# PIC32MX154F128D register map
Vendor: Microchip
Registers are 32-bit, read-write, reset 0x0 unless marked. A register's access mark holds for its fields unless they carry their own. Addresses are absolute, and some are shared; only a register's first bit layout is shown; [hi:lo] are bit positions; 'fields as' and 'values as' point back to an identical list.

## RTCC
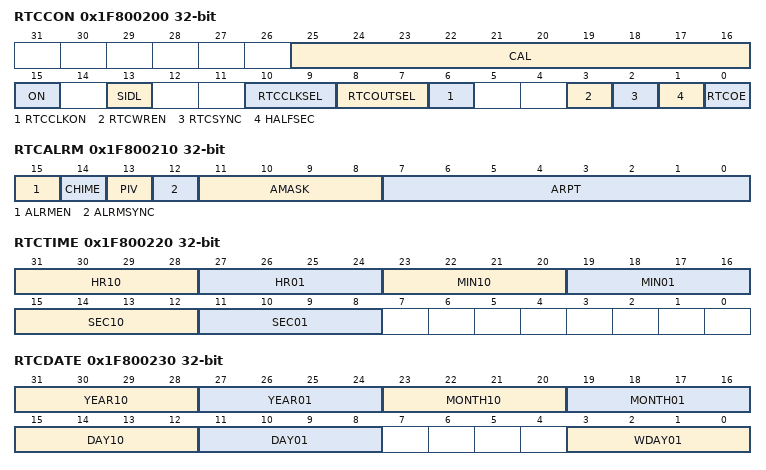
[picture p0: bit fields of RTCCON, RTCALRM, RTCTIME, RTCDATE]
0x1F800200 RTCCON
  [25:16] CAL, [15] ON, [13] SIDL, [10:9] RTCCLKSEL, [8:7] RTCOUTSEL, [6] RTCCLKON, [3] RTCWREN, [2] RTCSYNC ro, [1] HALFSEC ro, [0] RTCOE
0x1F800210 RTCALRM
  [15] ALRMEN, [14] CHIME, [13] PIV, [12] ALRMSYNC, [11:8] AMASK, [7:0] ARPT
0x1F800220 RTCTIME reset not defined — (power-on value 000xxxxxxxxxxxxx0xxxxxxx--------)
  [31:28] HR10, [27:24] HR01, [23:20] MIN10, [19:16] MIN01, [15:12] SEC10, [11:8] SEC01
0x1F800230 RTCDATE reset not defined — (power-on value xxxxxxxx000xxxxx00xxxxxx----0xxx)
  [31:28] YEAR10, [27:24] YEAR01, [23:20] MONTH10, [19:16] MONTH01, [15:12] DAY10, [11:8] DAY01, [3:0] WDAY01
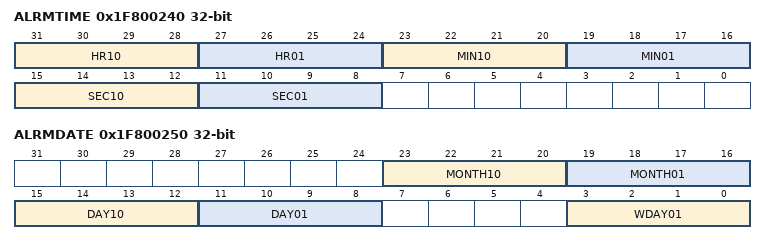
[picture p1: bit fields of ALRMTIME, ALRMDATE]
0x1F800240 ALRMTIME reset not defined — (power-on value 000xxxxx0xxxxxxx0xxxxxxx--------)
  fields as RTCTIME
0x1F800250 ALRMDATE reset not defined — (power-on value --------000xxxxx00xxxxxx----0xxx)
  [23:20] MONTH10, [19:16] MONTH01, [15:12] DAY10, [11:8] DAY01, [3:0] WDAY01

## TMR1
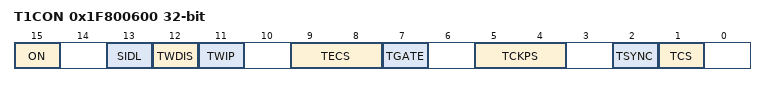
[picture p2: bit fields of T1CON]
0x1F800600 T1CON
  [15] ON, [13] SIDL, [12] TWDIS, [11] TWIP, [9:8] TECS, [7] TGATE, [5:4] TCKPS, [2] TSYNC, [1] TCS
0x1F800610 TMR1
0x1F800620 PR1 reset 0xFFFF

## TMR2
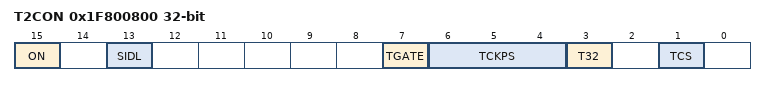
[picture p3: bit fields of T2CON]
0x1F800800 T2CON
  [15] ON, [13] SIDL, [7] TGATE, [6:4] TCKPS, [3] T32, [1] TCS
0x1F800810 TMR2
0x1F800820 PR2 reset 0xFFFF

## TMR3
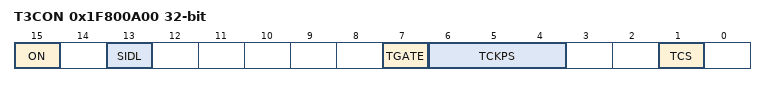
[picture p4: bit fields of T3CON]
0x1F800A00 T3CON
  [15] ON, [13] SIDL, [7] TGATE, [6:4] TCKPS, [1] TCS
0x1F800A10 TMR3
0x1F800A20 PR3 reset 0xFFFF

## TMR4
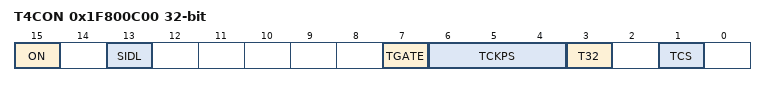
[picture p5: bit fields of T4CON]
0x1F800C00 T4CON
  [15] ON, [13] SIDL, [7] TGATE, [6:4] TCKPS, [3] T32, [1] TCS
0x1F800C10 TMR4
0x1F800C20 PR4 reset 0xFFFF

## TMR5
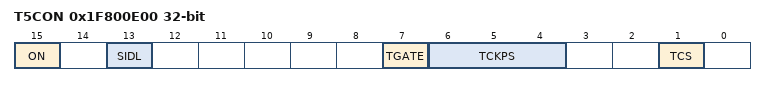
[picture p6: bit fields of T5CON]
0x1F800E00 T5CON
  [15] ON, [13] SIDL, [7] TGATE, [6:4] TCKPS, [1] TCS
0x1F800E10 TMR5
0x1F800E20 PR5 reset 0xFFFF

## ICAP1
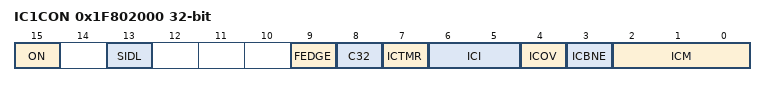
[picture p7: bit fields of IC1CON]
0x1F802000 IC1CON
  [15] ON, [13] SIDL, [9] FEDGE, [8] C32, [7] ICTMR, [6:5] ICI, [4] ICOV ro, [3] ICBNE ro, [2:0] ICM
0x1F802010 IC1BUF ro reset not defined — (power-on value xxxxxxxxxxxxxxxxxxxxxxxxxxxxxxxx)

## ICAP2
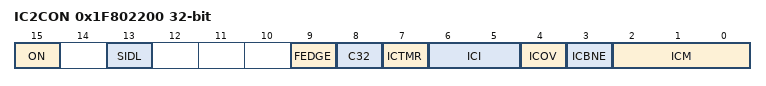
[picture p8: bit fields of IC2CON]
0x1F802200 IC2CON
  [15] ON, [13] SIDL, [9] FEDGE, [8] C32, [7] ICTMR, [6:5] ICI, [4] ICOV ro, [3] ICBNE ro, [2:0] ICM
0x1F802210 IC2BUF ro reset not defined — (power-on value xxxxxxxxxxxxxxxxxxxxxxxxxxxxxxxx)

## ICAP3
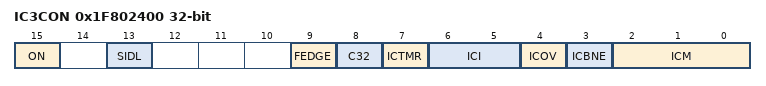
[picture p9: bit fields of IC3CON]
0x1F802400 IC3CON
  [15] ON, [13] SIDL, [9] FEDGE, [8] C32, [7] ICTMR, [6:5] ICI, [4] ICOV ro, [3] ICBNE ro, [2:0] ICM
0x1F802410 IC3BUF ro reset not defined — (power-on value xxxxxxxxxxxxxxxxxxxxxxxxxxxxxxxx)

## ICAP4
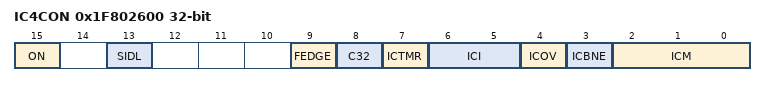
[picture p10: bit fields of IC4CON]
0x1F802600 IC4CON
  [15] ON, [13] SIDL, [9] FEDGE, [8] C32, [7] ICTMR, [6:5] ICI, [4] ICOV ro, [3] ICBNE ro, [2:0] ICM
0x1F802610 IC4BUF ro reset not defined — (power-on value xxxxxxxxxxxxxxxxxxxxxxxxxxxxxxxx)

## ICAP5
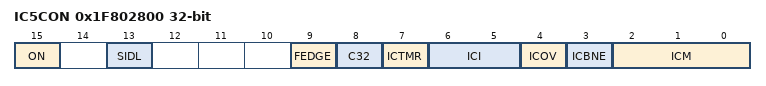
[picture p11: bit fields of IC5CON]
0x1F802800 IC5CON
  [15] ON, [13] SIDL, [9] FEDGE, [8] C32, [7] ICTMR, [6:5] ICI, [4] ICOV ro, [3] ICBNE ro, [2:0] ICM
0x1F802810 IC5BUF ro reset not defined — (power-on value xxxxxxxxxxxxxxxxxxxxxxxxxxxxxxxx)

## OCMP1
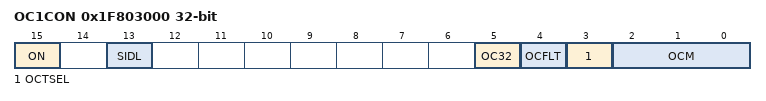
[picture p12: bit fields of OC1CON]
0x1F803000 OC1CON
  [15] ON, [13] SIDL, [5] OC32, [4] OCFLT ro, [3] OCTSEL, [2:0] OCM
0x1F803010 OC1R reset not defined — (power-on value xxxxxxxxxxxxxxxxxxxxxxxxxxxxxxxx)
0x1F803020 OC1RS reset not defined — (power-on value xxxxxxxxxxxxxxxxxxxxxxxxxxxxxxxx)

## OCMP2
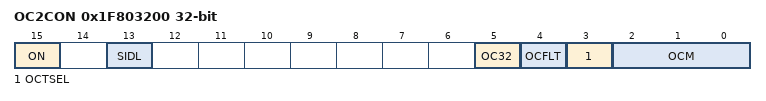
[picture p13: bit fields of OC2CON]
0x1F803200 OC2CON
  [15] ON, [13] SIDL, [5] OC32, [4] OCFLT ro, [3] OCTSEL, [2:0] OCM
0x1F803210 OC2R reset not defined — (power-on value xxxxxxxxxxxxxxxxxxxxxxxxxxxxxxxx)
0x1F803220 OC2RS reset not defined — (power-on value xxxxxxxxxxxxxxxxxxxxxxxxxxxxxxxx)

## OCMP3
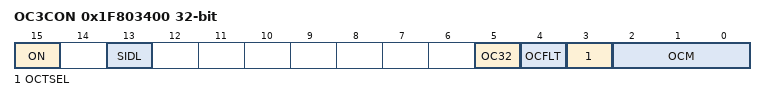
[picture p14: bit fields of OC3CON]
0x1F803400 OC3CON
  [15] ON, [13] SIDL, [5] OC32, [4] OCFLT ro, [3] OCTSEL, [2:0] OCM
0x1F803410 OC3R reset not defined — (power-on value xxxxxxxxxxxxxxxxxxxxxxxxxxxxxxxx)
0x1F803420 OC3RS reset not defined — (power-on value xxxxxxxxxxxxxxxxxxxxxxxxxxxxxxxx)
